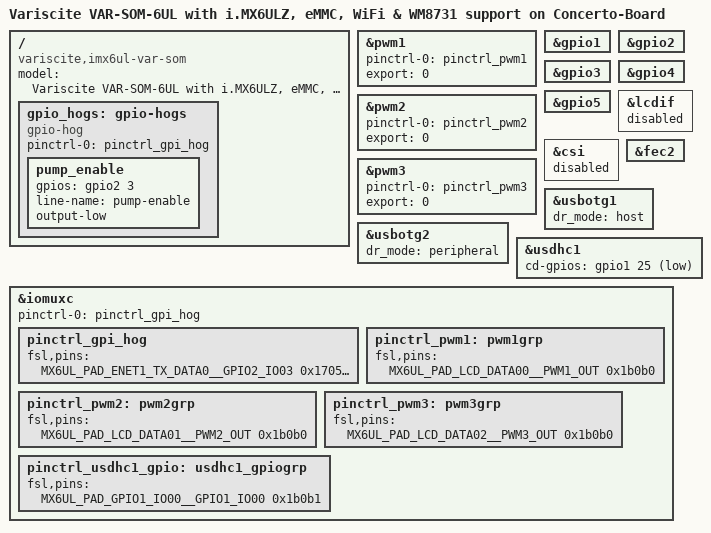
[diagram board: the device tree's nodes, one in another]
/dts-v1/;


#include "imx6ulz.dtsi"

#include "imx6ulz-var-som.dtsi"
#include "imx6ul-imx6ull-var-som-emmc.dtsi"
#include "imx6ul-imx6ull-var-som-wifi.dtsi"
#include "imx6ul-imx6ull-var-som-wm8731.dtsi"

#include "imx6ulz-var-som-concerto-board.dtsi"

/ {
        model = "Variscite VAR-SOM-6UL with i.MX6ULZ, eMMC, WiFi & WM8731 support on Concerto-Board";
        compatible = "variscite,imx6ul-var-som", "fsl,imx6ulz";


        gpio_hogs: gpio-hogs {
        compatible = "gpio-hog";
        pinctrl-names = "default";
        pinctrl-0 = <&pinctrl_gpi_hog>;

        pump_enable {
                  gpios = <&gpio2 3 GPIO_ACTIVE_HIGH>; /* GPIO2_IO03, Active High */
                  line-name = "pump-enable";
                  output-low; /* Set initial state to low */
                };
        };

};


/* PWM1 */
&pwm1 {
    pinctrl-names = "default";
    pinctrl-0 = <&pinctrl_pwm1>;
    status = "okay";
    export = <0>;
};

/* PWM2 */
&pwm2 {
    pinctrl-names = "default";
    pinctrl-0 = <&pinctrl_pwm2>;
    status = "okay";
    export = <0>;
};
/* PWM3 */
&pwm3 {
    pinctrl-names = "default";
    pinctrl-0 = <&pinctrl_pwm3>;
    status = "okay";
    export = <0>;
};


&gpio1 {
    status = "okay";
};

&gpio2 {  
    status = "okay";
};

&gpio3 {
    status = "okay";
};

&gpio4 {
    status = "okay";
};

&gpio5 {
    status = "okay";
};

&lcdif {
  status = "disabled";
};

&csi {
        status = "disabled";
};

&fec2 {
  status = "okay";
};

&usbotg1 {
    dr_mode = "host";  // Set the USB OTG controller to Host mode
    status = "okay";
};
&usbotg2 {
    dr_mode = "peripheral";  // Set the USB OTG2 to peripheral mode
    status = "okay";
};


&usdhc1 {
  cd-gpios = <&gpio1 25 GPIO_ACTIVE_LOW>;
};


&iomuxc {

  pinctrl-names = "default";
  pinctrl-0 = <&pinctrl_gpi_hog>;
  pinctrl_gpi_hog: pinctrl_gpi_hog {
      fsl,pins = <
          MX6UL_PAD_ENET1_TX_DATA0__GPIO2_IO03     0x17059  // PUMP_MICROEN_3v3
          MX6UL_PAD_ENET1_TX_CLK__GPIO2_IO06       0x17059   // PUMP_TEMPOK_3v3
          MX6UL_PAD_LCD_ENABLE__GPIO3_IO01         0x17059  // USBH_PWREN
          MX6UL_PAD_SNVS_TAMPER8__GPIO5_IO08       0x17059  // USBH_FAULT
          
      >;
  };

  /* PWM1 Pin */
  pinctrl_pwm1: pwm1grp {
      fsl,pins = <
          MX6UL_PAD_LCD_DATA00__PWM1_OUT          0x1b0b0
      >;
  };

  /* PWM2 Pin */
  pinctrl_pwm2: pwm2grp {
      fsl,pins = <
          MX6UL_PAD_LCD_DATA01__PWM2_OUT          0x1b0b0
      >;
  };

  /* PWM3 Pin */
  pinctrl_pwm3: pwm3grp {
      fsl,pins = <
          MX6UL_PAD_LCD_DATA02__PWM3_OUT          0x1b0b0
      >;
  };

  pinctrl_usdhc1_gpio: usdhc1_gpiogrp {
    fsl,pins = <
      MX6UL_PAD_GPIO1_IO00__GPIO1_IO00  0x1b0b1 /* CD */
    >;
  };

};

